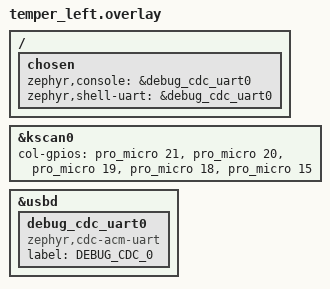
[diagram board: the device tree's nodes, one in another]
/*
 * Copyright (c) 2020 Pete Johanson
 *
 * SPDX-License-Identifier: MIT
 */

#include "temper.dtsi"

&kscan0 {
    col-gpios
        = <&pro_micro 21 GPIO_ACTIVE_HIGH>
        , <&pro_micro 20 GPIO_ACTIVE_HIGH>
        , <&pro_micro 19 GPIO_ACTIVE_HIGH>
        , <&pro_micro 18 GPIO_ACTIVE_HIGH>
        , <&pro_micro 15 GPIO_ACTIVE_HIGH>
        ;
};

/* TEMPORARY: extra CDC ACM console (separate from the Studio RPC CDC ACM
 * instance) to read raw battery ADC readings over USB serial while
 * debugging the charge issue. REVERT once diagnosed. */
&usbd {
    debug_cdc_uart0: debug_cdc_uart0 {
        compatible = "zephyr,cdc-acm-uart";
        label = "DEBUG_CDC_0";
    };
};

/ {
    chosen {
        zephyr,console = &debug_cdc_uart0;
        zephyr,shell-uart = &debug_cdc_uart0;
    };
};
